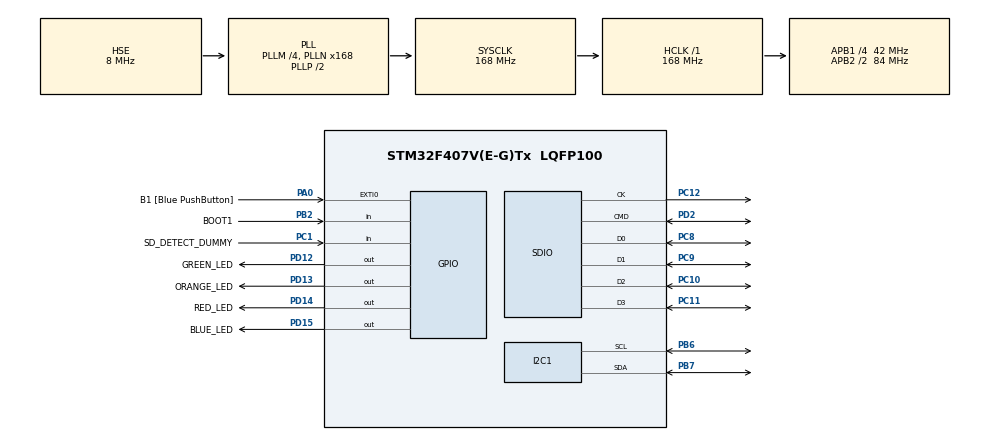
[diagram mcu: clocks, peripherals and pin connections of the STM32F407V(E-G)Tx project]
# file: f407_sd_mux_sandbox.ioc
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FATFS.BSP.number=1
FATFS._FS_EXFAT=1
FATFS._USE_LFN=1
FATFS0.BSP.STBoard=false
FATFS0.BSP.api=Unknown
FATFS0.BSP.instance=PC1
FATFS0.BSP.ip=GPIO
FATFS0.BSP.mode=Input
FATFS0.BSP.name=Detect_SDIO
FATFS0.BSP.solution=PC1
Mcu.Family=STM32F4
Mcu.Name=STM32F407V(E-G)Tx
Mcu.Package=LQFP100
NVIC.PriorityGroup=NVIC_PRIORITYGROUP_0
PA0-WKUP.GPIO_Label=B1 [Blue PushButton]
PA0-WKUP.GPIO_ModeDefaultEXTI=GPIO_MODE_EVT_RISING
PA0-WKUP.GPIO_PuPd=GPIO_NOPULL
PA0-WKUP.Signal=GPXTI0
PA13.GPIO_Label=SWDIO
PA13.Mode=Serial_Wire
PA13.Signal=SYS_JTMS-SWDIO
PA14.GPIO_Label=SWCLK
PA14.Mode=Serial_Wire
PA14.Signal=SYS_JTCK-SWCLK
PB2.GPIO_Label=BOOT1
PB2.GPIO_Mode=GPIO_MODE_INPUT
PB2.GPIO_PuPd=GPIO_NOPULL
PB2.Signal=GPIO_Input
PB6.Mode=I2C
PB6.Signal=I2C1_SCL
PB7.Mode=I2C
PB7.Signal=I2C1_SDA
PC1.GPIO_Label=SD_DETECT_DUMMY
PC1.GPIO_PuPd=GPIO_PULLDOWN
PC1.Signal=GPIO_Input
PC10.GPIO_Speed_High_Default=GPIO_SPEED_FREQ_MEDIUM
PC10.Mode=SD_4_bits_Wide_bus
PC10.Signal=SDIO_D2
PC11.GPIO_Speed_High_Default=GPIO_SPEED_FREQ_MEDIUM
PC11.Mode=SD_4_bits_Wide_bus
PC11.Signal=SDIO_D3
PC12.GPIO_Speed_High_Default=GPIO_SPEED_FREQ_MEDIUM
PC12.Mode=SD_4_bits_Wide_bus
PC12.Signal=SDIO_CK
PC14-OSC32_IN.GPIO_Label=PC14-OSC32_IN
PC14-OSC32_IN.Mode=LSE-External-Oscillator
PC14-OSC32_IN.Signal=RCC_OSC32_IN
PC15-OSC32_OUT.GPIO_Label=PC15-OSC32_OUT
PC15-OSC32_OUT.Mode=LSE-External-Oscillator
PC15-OSC32_OUT.Signal=RCC_OSC32_OUT
PC8.GPIO_Speed_High_Default=GPIO_SPEED_FREQ_MEDIUM
PC8.Mode=SD_4_bits_Wide_bus
PC8.Signal=SDIO_D0
PC9.GPIO_Speed_High_Default=GPIO_SPEED_FREQ_MEDIUM
PC9.Mode=SD_4_bits_Wide_bus
PC9.Signal=SDIO_D1
PD12.GPIO_Label=GREEN_LED
PD12.GPIO_PuPd=GPIO_NOPULL
PD12.GPIO_Speed=GPIO_SPEED_FREQ_LOW
PD12.Signal=GPIO_Output
PD13.GPIO_Label=ORANGE_LED
PD13.GPIO_PuPd=GPIO_NOPULL
PD13.GPIO_Speed=GPIO_SPEED_FREQ_LOW
PD13.Signal=GPIO_Output
PD14.GPIO_Label=RED_LED
PD14.GPIO_PuPd=GPIO_NOPULL
PD14.GPIO_Speed=GPIO_SPEED_FREQ_LOW
PD14.Signal=GPIO_Output
PD15.GPIO_Label=BLUE_LED
PD15.GPIO_PuPd=GPIO_NOPULL
PD15.GPIO_Speed=GPIO_SPEED_FREQ_LOW
PD15.Signal=GPIO_Output
PD2.GPIO_PuPd=GPIO_PULLUP
PD2.GPIO_Speed_High_Default=GPIO_SPEED_FREQ_MEDIUM
PD2.Mode=SD_4_bits_Wide_bus
PD2.Signal=SDIO_CMD
PH0-OSC_IN.GPIO_Label=PH0-OSC_IN
PH0-OSC_IN.Mode=HSE-External-Oscillator
PH0-OSC_IN.Signal=RCC_OSC_IN
PH1-OSC_OUT.GPIO_Label=PH1-OSC_OUT
PH1-OSC_OUT.Mode=HSE-External-Oscillator
PH1-OSC_OUT.Signal=RCC_OSC_OUT
ProjectManager.HeapSize=0x400
ProjectManager.StackSize=0x800
ProjectManager.TargetToolchain=STM32CubeIDE
RCC.48MHZClocksFreq_Value=48000000
RCC.AHBFreq_Value=168000000
RCC.APB1CLKDivider=RCC_HCLK_DIV4
RCC.APB1Freq_Value=42000000
RCC.APB1TimFreq_Value=84000000
RCC.APB2CLKDivider=RCC_HCLK_DIV2
RCC.APB2Freq_Value=84000000
RCC.APB2TimFreq_Value=168000000
RCC.CortexFreq_Value=168000000
RCC.HCLKFreq_Value=168000000
RCC.HSE_VALUE=8000000
RCC.HSI_VALUE=16000000
RCC.PLLM=4
RCC.PLLN=168
RCC.PLLQ=7
RCC.PLLSourceVirtual=RCC_PLLSOURCE_HSE
RCC.SYSCLKFreq_VALUE=168000000
RCC.SYSCLKSource=RCC_SYSCLKSOURCE_PLLCLK
RCC.VCOOutputFreq_Value=336000000
SDIO.ClockDiv=4
VP_FATFS_VS_SDIO.Mode=SDIO
board=STM32F407G-DISC1

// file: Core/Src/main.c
/* USER CODE BEGIN Header */
/**
 ******************************************************************************
 * @file           : main.c
 * @brief          : Main program body
 ******************************************************************************
 * @attention
 *
 * Copyright (c) 2024 STMicroelectronics.
 * All rights reserved.
 *
 * This software is licensed under terms that can be found in the LICENSE file
 * in the root directory of this software component.
 * If no LICENSE file comes with this software, it is provided AS-IS.
 *
 ******************************************************************************
 */
/* USER CODE END Header */
#include "main.h"
#include "fatfs.h"
#include "i2c.h"
#include "sdio.h"
#include "gpio.h"

/* USER CODE BEGIN Includes */

#include "app_main.h"

/* USER CODE END Includes */

void SystemClock_Config(void);

int main(void)
{

  /* MCU Configuration--------------------------------------------------------*/

  /* Reset of all peripherals, Initializes the Flash interface and the Systick. */
  HAL_Init();

  /* Configure the system clock */
  SystemClock_Config();

  /* Initialize all configured peripherals */
  MX_GPIO_Init();
  MX_I2C1_Init();
  MX_SDIO_SD_Init();
  MX_FATFS_Init();
  /* USER CODE BEGIN 2 */

  // call the user supplied main application entry point, which enters an infinite loop and never returns
  app_main();

  /* USER CODE END 2 */

  /* Infinite loop */
  /* USER CODE BEGIN WHILE */
  while (1)
  {
    // never reached

    /* USER CODE END WHILE */

  }
}

void SystemClock_Config(void)
{
  RCC_OscInitTypeDef RCC_OscInitStruct = {0};
  RCC_ClkInitTypeDef RCC_ClkInitStruct = {0};

  /** Configure the main internal regulator output voltage
  */
  __HAL_RCC_PWR_CLK_ENABLE();
  __HAL_PWR_VOLTAGESCALING_CONFIG(PWR_REGULATOR_VOLTAGE_SCALE1);

  /** Initializes the RCC Oscillators according to the specified parameters
  * in the RCC_OscInitTypeDef structure.
  */
  RCC_OscInitStruct.OscillatorType = RCC_OSCILLATORTYPE_HSE;
  RCC_OscInitStruct.HSEState = RCC_HSE_ON;
  RCC_OscInitStruct.PLL.PLLState = RCC_PLL_ON;
  RCC_OscInitStruct.PLL.PLLSource = RCC_PLLSOURCE_HSE;
  RCC_OscInitStruct.PLL.PLLM = 4;
  RCC_OscInitStruct.PLL.PLLN = 168;
  RCC_OscInitStruct.PLL.PLLP = RCC_PLLP_DIV2;
  RCC_OscInitStruct.PLL.PLLQ = 7;
  if (HAL_RCC_OscConfig(&RCC_OscInitStruct) != HAL_OK)
  {
    Error_Handler();
  }

  /** Initializes the CPU, AHB and APB buses clocks
  */
  RCC_ClkInitStruct.ClockType = RCC_CLOCKTYPE_HCLK|RCC_CLOCKTYPE_SYSCLK
                              |RCC_CLOCKTYPE_PCLK1|RCC_CLOCKTYPE_PCLK2;
  RCC_ClkInitStruct.SYSCLKSource = RCC_SYSCLKSOURCE_PLLCLK;
  RCC_ClkInitStruct.AHBCLKDivider = RCC_SYSCLK_DIV1;
  RCC_ClkInitStruct.APB1CLKDivider = RCC_HCLK_DIV4;
  RCC_ClkInitStruct.APB2CLKDivider = RCC_HCLK_DIV2;

  if (HAL_RCC_ClockConfig(&RCC_ClkInitStruct, FLASH_LATENCY_5) != HAL_OK)
  {
    Error_Handler();
  }
}

void Error_Handler(void)
{
  /* USER CODE BEGIN Error_Handler_Debug */
  /* User can add his own implementation to report the HAL error return state */
  //  __disable_irq();
  while (1)
  {
    HAL_GPIO_TogglePin(RED_LED_GPIO_Port, RED_LED_Pin);
    HAL_Delay(100);
  }
  /* USER CODE END Error_Handler_Debug */
}
